AUTOSAR XML (schema 00044)
package /ComponentTypes
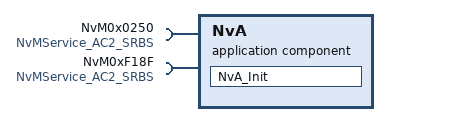
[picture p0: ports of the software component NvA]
  application sw component type NvA
    require port NvM0x0250: required-com-specs=[GetErrorStatus, ReadBlock, SetRamBlockStatus, WriteBlock], required-interface=NvMService_AC2_SRBS
    require port NvM0xF18F: required-com-specs=[GetErrorStatus, ReadBlock, SetRamBlockStatus, WriteBlock], required-interface=NvMService_AC2_SRBS
    behavior NvA_InternalBehavior
      init event NvA_InitEvent: start-on-event=NvA_Init
      runnable NvA_Init
        6 x sync call:
          SC_NvM_Service_0x0250_Integrity_validation_data_configuration_list_GetErrorStatus: operation=NvM0x0250.GetErrorStatus
          SC_NvM_Service_0x0250_Integrity_validation_data_configuration_list_ReadBlock: operation=NvM0x0250.ReadBlock
          SC_NvM_Service_0x0250_Integrity_validation_data_configuration_list_WriteBlock: operation=NvM0x0250.WriteBlock
          SC_Nvm_Service_0xF18F_Regulation_x_software_identification_numbers_GetErrorStatus: operation=NvM0xF18F.GetErrorStatus
          SC_Nvm_Service_0xF18F_Regulation_x_software_identification_numbers_ReadBlock: operation=NvM0xF18F.ReadBlock
          SC_Nvm_Service_0xF18F_Regulation_x_software_identification_numbers_WriteBlock: operation=NvM0xF18F.WriteBlock
  swc implementation NvA_Implementation: vendor-id=75, behavior=NvA_InternalBehavior
    code-descriptors:
      code Default: artifact-descriptors=autosar-engineering-object=category=SWSRC
    resource consumption ResourceConsumption
      memory section CODE: sw-addrmethod=CODE
      memory section CONST_UNSPECIFIED: alignment=UNSPECIFIED, sw-addrmethod=CONST
